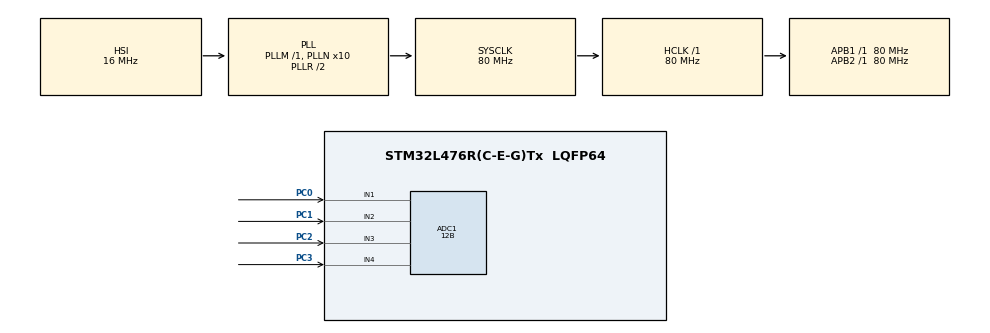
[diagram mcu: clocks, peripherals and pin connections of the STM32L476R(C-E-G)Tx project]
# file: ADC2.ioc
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ADC1.Channel-0\#ChannelRegularConversion=ADC_CHANNEL_1
ADC1.Channel-1\#ChannelRegularConversion=ADC_CHANNEL_2
ADC1.Channel-10\#ChannelRegularConversion=ADC_CHANNEL_1
ADC1.Channel-2\#ChannelRegularConversion=ADC_CHANNEL_3
ADC1.ClockPrescaler=ADC_CLOCK_ASYNC_DIV1
ADC1.ContinuousConvMode=ENABLE
ADC1.DMAContinuousRequests=ENABLE
ADC1.DataAlign=ADC_DATAALIGN_RIGHT
ADC1.DiscontinuousConvMode=DISABLE
ADC1.EOCSelection=ADC_EOC_SINGLE_CONV
ADC1.EnableAnalogWatchDog1=false
ADC1.EnableAnalogWatchDog2=false
ADC1.EnableAnalogWatchDog3=false
ADC1.EnableInjectedConversion=DISABLE
ADC1.EnableRegularConversion=ENABLE
ADC1.ExternalTrigConv=ADC_SOFTWARE_START
ADC1.ExternalTrigConvEdge=ADC_EXTERNALTRIGCONVEDGE_NONE
ADC1.LowPowerAutoWait=DISABLE
ADC1.NbrOfConversion=4
ADC1.NbrOfConversionFlag=1
ADC1.OffsetNumber-0\#ChannelRegularConversion=ADC_OFFSET_NONE
ADC1.OffsetNumber-1\#ChannelRegularConversion=ADC_OFFSET_NONE
ADC1.OffsetNumber-10\#ChannelRegularConversion=ADC_OFFSET_NONE
ADC1.OffsetNumber-2\#ChannelRegularConversion=ADC_OFFSET_NONE
ADC1.Overrun=ADC_OVR_DATA_PRESERVED
ADC1.OversamplingMode=DISABLE
ADC1.Rank-0\#ChannelRegularConversion=1
ADC1.Rank-1\#ChannelRegularConversion=2
ADC1.Rank-10\#ChannelRegularConversion=4
ADC1.Rank-2\#ChannelRegularConversion=3
ADC1.Resolution=ADC_RESOLUTION_12B
ADC1.SamplingTime-0\#ChannelRegularConversion=ADC_SAMPLETIME_640CYCLES_5
ADC1.SamplingTime-1\#ChannelRegularConversion=ADC_SAMPLETIME_640CYCLES_5
ADC1.SamplingTime-10\#ChannelRegularConversion=ADC_SAMPLETIME_640CYCLES_5
ADC1.SamplingTime-2\#ChannelRegularConversion=ADC_SAMPLETIME_640CYCLES_5
ADC1.ScanConvMode=ADC_SCAN_ENABLE
ADC1.master=1
Dma.ADC1.0.Direction=DMA_PERIPH_TO_MEMORY
Dma.ADC1.0.Instance=DMA1_Channel1
Dma.ADC1.0.MemDataAlignment=DMA_MDATAALIGN_HALFWORD
Dma.ADC1.0.MemInc=DMA_MINC_ENABLE
Dma.ADC1.0.Mode=DMA_CIRCULAR
Dma.ADC1.0.PeriphDataAlignment=DMA_PDATAALIGN_HALFWORD
Dma.ADC1.0.PeriphInc=DMA_PINC_DISABLE
Dma.ADC1.0.Priority=DMA_PRIORITY_LOW
Dma.Request0=ADC1
Mcu.Family=STM32L4
Mcu.Name=STM32L476R(C-E-G)Tx
Mcu.Package=LQFP64
NVIC.ADC1_2_IRQn=true\:0\:0\:false\:false\:true\:true
NVIC.DMA1_Channel1_IRQn=true\:0\:0\:false\:false\:true\:false
NVIC.PriorityGroup=NVIC_PRIORITYGROUP_4
PA13\ (JTMS-SWDIO).Mode=Serial_Wire
PA13\ (JTMS-SWDIO).Signal=SYS_JTMS-SWDIO
PA14\ (JTCK-SWCLK).Mode=Serial_Wire
PA14\ (JTCK-SWCLK).Signal=SYS_JTCK-SWCLK
PC0.Signal=ADCx_IN1
PC1.Signal=ADCx_IN2
PC2.Signal=ADCx_IN3
PC3.Signal=ADCx_IN4
ProjectManager.HeapSize=0x200
ProjectManager.StackSize=0x400
ProjectManager.TargetToolchain=MDK-ARM V5
RCC.ADCFreq_Value=64000000
RCC.AHBFreq_Value=80000000
RCC.APB1Freq_Value=80000000
RCC.APB1TimFreq_Value=80000000
RCC.APB2Freq_Value=80000000
RCC.APB2TimFreq_Value=80000000
RCC.CortexFreq_Value=80000000
RCC.HCLKFreq_Value=80000000
RCC.HSE_VALUE=8000000
RCC.HSI_VALUE=16000000
RCC.LSE_VALUE=32768
RCC.MSI_VALUE=4000000
RCC.PLLN=10
RCC.PLLSourceVirtual=RCC_PLLSOURCE_HSI
RCC.SYSCLKFreq_VALUE=80000000
RCC.SYSCLKSource=RCC_SYSCLKSOURCE_PLLCLK
RCC.USBFreq_Value=64000000
RCC.VCOOutputFreq_Value=160000000
SH.ADCx_IN1.0=ADC1_IN1,IN1-Single-Ended
SH.ADCx_IN2.0=ADC1_IN2,IN2-Single-Ended
SH.ADCx_IN3.0=ADC1_IN3,IN3-Single-Ended
SH.ADCx_IN4.0=ADC1_IN4,IN4-Single-Ended
board=ADC2

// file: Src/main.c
/**
  ******************************************************************************
  * File Name          : main.c
  * Description        : Main program body
  ******************************************************************************
  ** This notice applies to any and all portions of this file
  * that are not between comment pairs USER CODE BEGIN and
  * USER CODE END. Other portions of this file, whether
  * inserted by the user or by software development tools
  * are owned by their respective copyright owners.
  *
  * COPYRIGHT(c) 2018 STMicroelectronics
  *
  * Redistribution and use in source and binary forms, with or without modification,
  * are permitted provided that the following conditions are met:
  *   1. Redistributions of source code must retain the above copyright notice,
  *      this list of conditions and the following disclaimer.
  *   2. Redistributions in binary form must reproduce the above copyright notice,
  *      this list of conditions and the following disclaimer in the documentation
  *      and/or other materials provided with the distribution.
  *   3. Neither the name of STMicroelectronics nor the names of its contributors
  *      may be used to endorse or promote products derived from this software
  *      without specific prior written permission.
  *
  * THIS SOFTWARE IS PROVIDED BY THE COPYRIGHT HOLDERS AND CONTRIBUTORS "AS IS"
  * AND ANY EXPRESS OR IMPLIED WARRANTIES, INCLUDING, BUT NOT LIMITED TO, THE
  * IMPLIED WARRANTIES OF MERCHANTABILITY AND FITNESS FOR A PARTICULAR PURPOSE ARE
  * DISCLAIMED. IN NO EVENT SHALL THE COPYRIGHT HOLDER OR CONTRIBUTORS BE LIABLE
  * FOR ANY DIRECT, INDIRECT, INCIDENTAL, SPECIAL, EXEMPLARY, OR CONSEQUENTIAL
  * DAMAGES (INCLUDING, BUT NOT LIMITED TO, PROCUREMENT OF SUBSTITUTE GOODS OR
  * SERVICES; LOSS OF USE, DATA, OR PROFITS; OR BUSINESS INTERRUPTION) HOWEVER
  * CAUSED AND ON ANY THEORY OF LIABILITY, WHETHER IN CONTRACT, STRICT LIABILITY,
  * OR TORT (INCLUDING NEGLIGENCE OR OTHERWISE) ARISING IN ANY WAY OUT OF THE USE
  * OF THIS SOFTWARE, EVEN IF ADVISED OF THE POSSIBILITY OF SUCH DAMAGE.
  *
  ******************************************************************************
  */

#include "main.h"
#include "stm32l4xx_hal.h"

ADC_HandleTypeDef hadc1;
DMA_HandleTypeDef hdma_adc1;

/* USER CODE BEGIN PV */
/* Private variables ---------------------------------------------------------*/

/* USER CODE END PV */

void SystemClock_Config(void);
static void MX_GPIO_Init(void);
static void MX_DMA_Init(void);
static void MX_ADC1_Init(void);

/* USER CODE BEGIN PFP */
/* Private function prototypes -----------------------------------------------*/
uint16_t adc_value[4];
/* USER CODE END PFP */

int main(void)
{

  /* MCU Configuration----------------------------------------------------------*/

  /* Reset of all peripherals, Initializes the Flash interface and the Systick. */
  HAL_Init();

  /* Configure the system clock */
  SystemClock_Config();

  /* Initialize all configured peripherals */
  MX_GPIO_Init();
  MX_DMA_Init();
  MX_ADC1_Init();

  /* USER CODE BEGIN 2 */
	HAL_ADC_Start_DMA(&hadc1,(uint32_t *)adc_value,4);
	HAL_ADC_Stop_DMA(&hadc1);
  /* USER CODE END 2 */

  /* Infinite loop */
  while (1)
  {

  }

}

/** System Clock Configuration
*/
void SystemClock_Config(void)
{

  RCC_OscInitTypeDef RCC_OscInitStruct;
  RCC_ClkInitTypeDef RCC_ClkInitStruct;
  RCC_PeriphCLKInitTypeDef PeriphClkInit;

    /**Initializes the CPU, AHB and APB busses clocks
    */
  RCC_OscInitStruct.OscillatorType = RCC_OSCILLATORTYPE_HSI;
  RCC_OscInitStruct.HSIState = RCC_HSI_ON;
  RCC_OscInitStruct.HSICalibrationValue = 16;
  RCC_OscInitStruct.PLL.PLLState = RCC_PLL_ON;
  RCC_OscInitStruct.PLL.PLLSource = RCC_PLLSOURCE_HSI;
  RCC_OscInitStruct.PLL.PLLM = 1;
  RCC_OscInitStruct.PLL.PLLN = 10;
  RCC_OscInitStruct.PLL.PLLP = RCC_PLLP_DIV7;
  RCC_OscInitStruct.PLL.PLLQ = RCC_PLLQ_DIV2;
  RCC_OscInitStruct.PLL.PLLR = RCC_PLLR_DIV2;
  if (HAL_RCC_OscConfig(&RCC_OscInitStruct) != HAL_OK)
  {
    _Error_Handler(__FILE__, __LINE__);
  }

    /**Initializes the CPU, AHB and APB busses clocks
    */
  RCC_ClkInitStruct.ClockType = RCC_CLOCKTYPE_HCLK|RCC_CLOCKTYPE_SYSCLK
                              |RCC_CLOCKTYPE_PCLK1|RCC_CLOCKTYPE_PCLK2;
  RCC_ClkInitStruct.SYSCLKSource = RCC_SYSCLKSOURCE_PLLCLK;
  RCC_ClkInitStruct.AHBCLKDivider = RCC_SYSCLK_DIV1;
  RCC_ClkInitStruct.APB1CLKDivider = RCC_HCLK_DIV1;
  RCC_ClkInitStruct.APB2CLKDivider = RCC_HCLK_DIV1;

  if (HAL_RCC_ClockConfig(&RCC_ClkInitStruct, FLASH_LATENCY_3) != HAL_OK)
  {
    _Error_Handler(__FILE__, __LINE__);
  }

  PeriphClkInit.PeriphClockSelection = RCC_PERIPHCLK_ADC;
  PeriphClkInit.AdcClockSelection = RCC_ADCCLKSOURCE_PLLSAI1;
  PeriphClkInit.PLLSAI1.PLLSAI1Source = RCC_PLLSOURCE_HSI;
  PeriphClkInit.PLLSAI1.PLLSAI1M = 1;
  PeriphClkInit.PLLSAI1.PLLSAI1N = 8;
  PeriphClkInit.PLLSAI1.PLLSAI1P = RCC_PLLP_DIV7;
  PeriphClkInit.PLLSAI1.PLLSAI1Q = RCC_PLLQ_DIV2;
  PeriphClkInit.PLLSAI1.PLLSAI1R = RCC_PLLR_DIV2;
  PeriphClkInit.PLLSAI1.PLLSAI1ClockOut = RCC_PLLSAI1_ADC1CLK;
  if (HAL_RCCEx_PeriphCLKConfig(&PeriphClkInit) != HAL_OK)
  {
    _Error_Handler(__FILE__, __LINE__);
  }

    /**Configure the main internal regulator output voltage
    */
  if (HAL_PWREx_ControlVoltageScaling(PWR_REGULATOR_VOLTAGE_SCALE1) != HAL_OK)
  {
    _Error_Handler(__FILE__, __LINE__);
  }

    /**Configure the Systick interrupt time
    */
  HAL_SYSTICK_Config(HAL_RCC_GetHCLKFreq()/1000);

    /**Configure the Systick
    */
  HAL_SYSTICK_CLKSourceConfig(SYSTICK_CLKSOURCE_HCLK);

  /* SysTick_IRQn interrupt configuration */
  HAL_NVIC_SetPriority(SysTick_IRQn, 0, 0);
}

/* ADC1 init function */
static void MX_ADC1_Init(void)
{

  ADC_MultiModeTypeDef multimode;
  ADC_ChannelConfTypeDef sConfig;

    /**Common config
    */
  hadc1.Instance = ADC1;
  hadc1.Init.ClockPrescaler = ADC_CLOCK_ASYNC_DIV1;
  hadc1.Init.Resolution = ADC_RESOLUTION_12B;
  hadc1.Init.DataAlign = ADC_DATAALIGN_RIGHT;
  hadc1.Init.ScanConvMode = ADC_SCAN_ENABLE;
  hadc1.Init.EOCSelection = ADC_EOC_SINGLE_CONV;
  hadc1.Init.LowPowerAutoWait = DISABLE;
  hadc1.Init.ContinuousConvMode = ENABLE;
  hadc1.Init.NbrOfConversion = 4;
  hadc1.Init.DiscontinuousConvMode = DISABLE;
  hadc1.Init.NbrOfDiscConversion = 1;
  hadc1.Init.ExternalTrigConv = ADC_SOFTWARE_START;
  hadc1.Init.ExternalTrigConvEdge = ADC_EXTERNALTRIGCONVEDGE_NONE;
  hadc1.Init.DMAContinuousRequests = ENABLE;
  hadc1.Init.Overrun = ADC_OVR_DATA_PRESERVED;
  hadc1.Init.OversamplingMode = DISABLE;
  if (HAL_ADC_Init(&hadc1) != HAL_OK)
  {
    _Error_Handler(__FILE__, __LINE__);
  }

    /**Configure the ADC multi-mode
    */
  multimode.Mode = ADC_MODE_INDEPENDENT;
  if (HAL_ADCEx_MultiModeConfigChannel(&hadc1, &multimode) != HAL_OK)
  {
    _Error_Handler(__FILE__, __LINE__);
  }

    /**Configure Regular Channel
    */
  sConfig.Channel = ADC_CHANNEL_1;
  sConfig.Rank = 1;
  sConfig.SamplingTime = ADC_SAMPLETIME_640CYCLES_5;
  sConfig.SingleDiff = ADC_SINGLE_ENDED;
  sConfig.OffsetNumber = ADC_OFFSET_NONE;
  sConfig.Offset = 0;
  if (HAL_ADC_ConfigChannel(&hadc1, &sConfig) != HAL_OK)
  {
    _Error_Handler(__FILE__, __LINE__);
  }

    /**Configure Regular Channel
    */
  sConfig.Channel = ADC_CHANNEL_2;
  sConfig.Rank = 2;
  if (HAL_ADC_ConfigChannel(&hadc1, &sConfig) != HAL_OK)
  {
    _Error_Handler(__FILE__, __LINE__);
  }

    /**Configure Regular Channel
    */
  sConfig.Channel = ADC_CHANNEL_3;
  sConfig.Rank = 3;
  if (HAL_ADC_ConfigChannel(&hadc1, &sConfig) != HAL_OK)
  {
    _Error_Handler(__FILE__, __LINE__);
  }

    /**Configure Regular Channel
    */
  sConfig.Channel = ADC_CHANNEL_1;
  sConfig.Rank = 4;
  if (HAL_ADC_ConfigChannel(&hadc1, &sConfig) != HAL_OK)
  {
    _Error_Handler(__FILE__, __LINE__);
  }

}

static void MX_DMA_Init(void)
{
  /* DMA controller clock enable */
  __HAL_RCC_DMA1_CLK_ENABLE();

  /* DMA interrupt init */
  /* DMA1_Channel1_IRQn interrupt configuration */
  HAL_NVIC_SetPriority(DMA1_Channel1_IRQn, 0, 0);
  HAL_NVIC_EnableIRQ(DMA1_Channel1_IRQn);

}

/** Configure pins as
        * Analog
        * Input
        * Output
        * EVENT_OUT
        * EXTI
*/
static void MX_GPIO_Init(void)
{

  /* GPIO Ports Clock Enable */
  __HAL_RCC_GPIOC_CLK_ENABLE();
  __HAL_RCC_GPIOA_CLK_ENABLE();

}

void _Error_Handler(char * file, int line)
{
  while(1)
  {
  }
}

/************************ (C) COPYRIGHT STMicroelectronics *****END OF FILE****/
